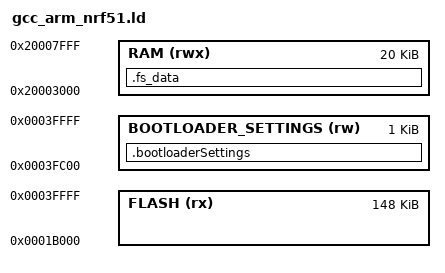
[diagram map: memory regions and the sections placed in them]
/* Linker script to configure memory regions. */

SEARCH_DIR(.)
GROUP(-lgcc -lc -lnosys)

MEMORY
{
  FLASH (rx) : ORIGIN = 0x1b000, LENGTH = 0x25000
  RAM (rwx) :  ORIGIN = 0x20003000, LENGTH = 0x5000
  BOOTLOADER_SETTINGS (rw) : ORIGIN = 0x0003FC00, LENGTH = 0x400
}

SECTIONS
{
/* Place the bootloader settings page in flash. */
  .bootloaderSettings(NOLOAD) :
  {

  } > BOOTLOADER_SETTINGS
  
  .fs_data :
  {
    PROVIDE(__start_fs_data = .);
    KEEP(*(.fs_data))
    PROVIDE(__stop_fs_data = .);
  } > RAM
} INSERT AFTER .data;

INCLUDE "nrf5x_common.ld"
